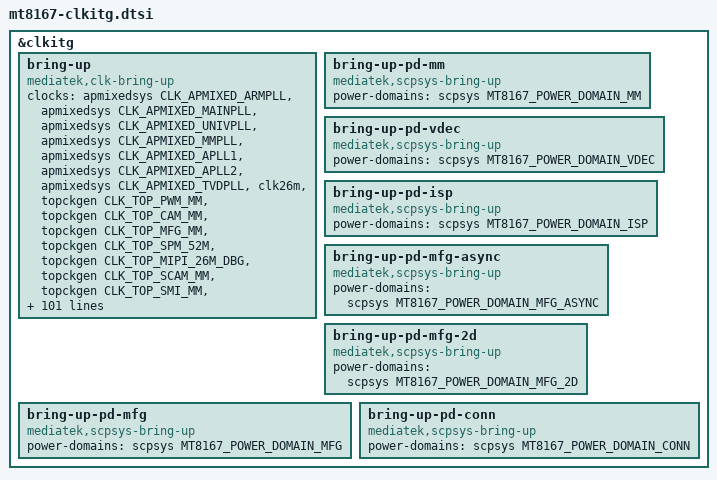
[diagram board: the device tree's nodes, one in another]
&clkitg {
	bring-up {
		compatible = "mediatek,clk-bring-up";
		clocks =
			<&apmixedsys CLK_APMIXED_ARMPLL>,
			<&apmixedsys CLK_APMIXED_MAINPLL>,
			<&apmixedsys CLK_APMIXED_UNIVPLL>,
			<&apmixedsys CLK_APMIXED_MMPLL>,
			<&apmixedsys CLK_APMIXED_APLL1>,
			<&apmixedsys CLK_APMIXED_APLL2>,
			<&apmixedsys CLK_APMIXED_TVDPLL>,
			<&clk26m>,
			<&topckgen CLK_TOP_PWM_MM>,
			<&topckgen CLK_TOP_CAM_MM>,
			<&topckgen CLK_TOP_MFG_MM>,
			<&topckgen CLK_TOP_SPM_52M>,
			<&topckgen CLK_TOP_MIPI_26M_DBG>,
			<&topckgen CLK_TOP_SCAM_MM>,
			<&topckgen CLK_TOP_SMI_MM>,
			<&topckgen CLK_TOP_THEM>,
			<&topckgen CLK_TOP_APDMA>,
			<&topckgen CLK_TOP_I2C0>,
			<&topckgen CLK_TOP_I2C1>,
			<&topckgen CLK_TOP_AUXADC1>,
			<&topckgen CLK_TOP_NFI>,
			<&topckgen CLK_TOP_NFIECC>,
			<&topckgen CLK_TOP_DEBUGSYS>,
			<&topckgen CLK_TOP_PWM>,
			<&topckgen CLK_TOP_UART0>,
			<&topckgen CLK_TOP_UART1>,
			<&topckgen CLK_TOP_BTIF>,
			<&topckgen CLK_TOP_USB>,
			<&topckgen CLK_TOP_FLASHIF_26M>,
			<&topckgen CLK_TOP_AUXADC2>,
			<&topckgen CLK_TOP_I2C2>,
			<&clk26m>,
			<&clk26m>,
			<&topckgen CLK_TOP_NFI2X>,
			<&clk26m>,
			<&topckgen CLK_TOP_SEJ>,
			<&topckgen CLK_TOP_MEMSLP_DLYER>,
			<&topckgen CLK_TOP_SPI>,
			<&topckgen CLK_TOP_APXGPT>,
			<&clk26m>,
			<&clk26m>,
			<&clk26m>,
			<&clk26m>,
			<&topckgen CLK_TOP_AUX_ADC>,
			<&topckgen CLK_TOP_AUX_TP>,
			<&topckgen CLK_TOP_MSDC2>,
			<&topckgen CLK_TOP_RBIST>,
			<&topckgen CLK_TOP_NFI_BUS>,
			<&topckgen CLK_TOP_GCE>,
			<&topckgen CLK_TOP_TRNG>,
			<&topckgen CLK_TOP_SEJ_13M>,
			<&topckgen CLK_TOP_AES>,
			<&topckgen CLK_TOP_PWM_B>,
			<&topckgen CLK_TOP_PWM1_FB>,
			<&topckgen CLK_TOP_PWM2_FB>,
			<&topckgen CLK_TOP_PWM3_FB>,
			<&topckgen CLK_TOP_PWM4_FB>,
			<&topckgen CLK_TOP_PWM5_FB>,
			<&topckgen CLK_TOP_USB_1P>,
			<&topckgen CLK_TOP_FLASHIF_FREERUN>,
			<&topckgen CLK_TOP_26M_HDMI_SIFM>,
			<&topckgen CLK_TOP_26M_CEC>,
			<&topckgen CLK_TOP_32K_CEC>,
			<&topckgen CLK_TOP_66M_ETH>,
			<&topckgen CLK_TOP_133M_ETH>,
			<&topckgen CLK_TOP_FETH_25M>,
			<&topckgen CLK_TOP_FETH_50M>,
			<&topckgen CLK_TOP_FLASHIF_AXI>,
			<&topckgen CLK_TOP_USBIF>,
			<&topckgen CLK_TOP_UART2>,
			<&topckgen CLK_TOP_BSI>,
			<&topckgen CLK_TOP_GCPU_B>,
			<&topckgen CLK_TOP_RG_SPINOR>,
			<&topckgen CLK_TOP_RG_MSDC2>,
			<&topckgen CLK_TOP_RG_ETH>,
			<&topckgen CLK_TOP_RG_VDEC>,
			<&clk26m>,
			<&topckgen CLK_TOP_RG_FDPI1>,
			<&topckgen CLK_TOP_RG_AXI_MFG>,
			<&topckgen CLK_TOP_RG_SLOW_MFG>,
			<&clk26m>,
			<&clk26m>,
			<&clk26m>,
			<&clk26m>,
			<&topckgen CLK_TOP_RG_I2C>,
			<&topckgen CLK_TOP_RG_PWM_INFRA>,
			<&clk26m>,
			<&topckgen CLK_TOP_RG_UART2>,
			<&topckgen CLK_TOP_RG_BSI>,
			<&topckgen CLK_TOP_RG_DBG_ATCLK>,
			<&topckgen CLK_TOP_RG_NFIECC>,
			<&clk26m>,
			<&clk26m>,
			<&clk26m>,
			<&clk26m>,
			<&clk26m>,
			<&clk26m>,
			<&clk26m>,
			<&clk26m>,
			<&clk26m>,
			<&clk26m>,
			<&clk26m>,
			<&clk26m>,
			<&clk26m>,
			<&clk26m>,
			<&clk26m>,
			<&clk26m>,
			<&clk26m>,
			<&clk26m>,
			<&clk26m>,
			<&clk26m>,
			<&clk26m>,
			<&clk26m>,
			<&clk26m>,
			<&clk26m>,
			<&clk26m>,
			<&clk26m>,
			<&clk26m>,
			<&clk26m>,
			<&mfgcfg CLK_MFG_BAXI>,
			<&mfgcfg CLK_MFG_BMEM>,
			<&mfgcfg CLK_MFG_BG3D>,
			<&mfgcfg CLK_MFG_B26M>,
			<&clk26m>,
			<&clk26m>,
			<&mmsys CLK_MM_CAM_MDP>,
			<&mmsys CLK_MM_MDP_RDMA>,
			<&mmsys CLK_MM_MDP_RSZ0>,
			<&mmsys CLK_MM_MDP_RSZ1>,
			<&mmsys CLK_MM_MDP_TDSHP>,
			<&mmsys CLK_MM_MDP_WDMA>,
			<&mmsys CLK_MM_MDP_WROT>,
			<&mmsys CLK_MM_FAKE_ENG>,
			<&mmsys CLK_MM_DISP_OVL0>,
			<&mmsys CLK_MM_DISP_RDMA0>,
			<&mmsys CLK_MM_DISP_RDMA1>,
			<&mmsys CLK_MM_DISP_WDMA>,
			<&mmsys CLK_MM_DISP_COLOR>,
			<&mmsys CLK_MM_DISP_CCORR>,
			<&mmsys CLK_MM_DISP_AAL>,
			<&mmsys CLK_MM_DISP_GAMMA>,
			<&mmsys CLK_MM_DISP_DITHER>,
			<&mmsys CLK_MM_DISP_UFOE_>,
			<&mmsys CLK_MM_DISP_PWM_MM>,
			<&mmsys CLK_MM_DISP_PWM_26M>,
			<&mmsys CLK_MM_DSI_ENGINE>,
			<&mmsys CLK_MM_DSI_DIGITAL>,
			<&clk26m>,
			<&clk26m>,
			<&clk26m>,
			<&clk26m>,
			<&clk26m>,
			<&clk26m>,
			<&mmsys CLK_MM_HDMI_PXL>,
			<&mmsys CLK_MM_HDMI_SPDIF>,
			<&mmsys CLK_MM_HDMI_ADSP_BCK>,
			<&mmsys CLK_MM_HDMI_PLL>,
			<&clk26m>,
			<&clk26m>,
			<&imgsys CLK_IMG_CAM_CAM>,
			<&imgsys CLK_IMG_SEN_TG>,
			<&imgsys CLK_IMG_SEN_CAM>,
			<&imgsys CLK_IMG_VENC>,
			<&clk26m>,
			<&clk26m>,
			<&clk26m>,
			<&clk26m>,
			<&clk26m>,
			<&clk26m>,
			<&clk26m>;

		clock-names =
			"0", "1", "2", "3", "4", "5", "6", "7", "8", "9",
			"10", "11", "12", "13", "14", "15", "16", "17", "18", "19",
			"20", "21", "22", "23", "24", "25", "26", "27", "28", "29",
			"30", "31", "32", "33", "34", "35", "36", "37", "38", "39",
			"40", "41", "42", "43", "44", "45", "46", "47", "48", "49",
			"50", "51", "52", "53", "54", "55", "56", "57", "58", "59",
			"60", "61", "62", "63", "64", "65", "66", "67", "68", "69",
			"70", "71", "72", "73", "74", "75", "76", "77", "78", "79",
			"80", "81", "82", "83", "84", "85", "86", "87", "88", "89",
			"90", "91", "92", "93", "94", "95", "96", "97", "98", "99",
			"100", "101", "102", "103", "104", "105", "106", "107", "108", "109",
			"110", "111", "112", "113", "114", "115", "116", "117", "118", "119",
			"120", "121", "122", "123", "124", "125", "126", "127", "128", "129",
			"130", "131", "132", "133", "134", "135", "136", "137", "138", "139",
			"140", "141", "142", "143", "144", "145", "146", "147", "148", "149",
			"150", "151", "152", "153", "154", "155", "156", "157", "158", "159",
			"160", "161", "162", "163", "164", "165", "166", "167", "168", "169";
	};

	bring-up-pd-mm {
		compatible = "mediatek,scpsys-bring-up";
		power-domains = <&scpsys MT8167_POWER_DOMAIN_MM>;
	};

	bring-up-pd-vdec {
		compatible = "mediatek,scpsys-bring-up";
		power-domains = <&scpsys MT8167_POWER_DOMAIN_VDEC>;
	};

	bring-up-pd-isp {
		compatible = "mediatek,scpsys-bring-up";
		power-domains = <&scpsys MT8167_POWER_DOMAIN_ISP>;
	};

	bring-up-pd-mfg-async {
		compatible = "mediatek,scpsys-bring-up";
		power-domains = <&scpsys MT8167_POWER_DOMAIN_MFG_ASYNC>;
	};

	bring-up-pd-mfg-2d {
		compatible = "mediatek,scpsys-bring-up";
		power-domains = <&scpsys MT8167_POWER_DOMAIN_MFG_2D>;
	};

	bring-up-pd-mfg {
		compatible = "mediatek,scpsys-bring-up";
		power-domains = <&scpsys MT8167_POWER_DOMAIN_MFG>;
	};

	bring-up-pd-conn {
		compatible = "mediatek,scpsys-bring-up";
		power-domains = <&scpsys MT8167_POWER_DOMAIN_CONN>;
	};
};
